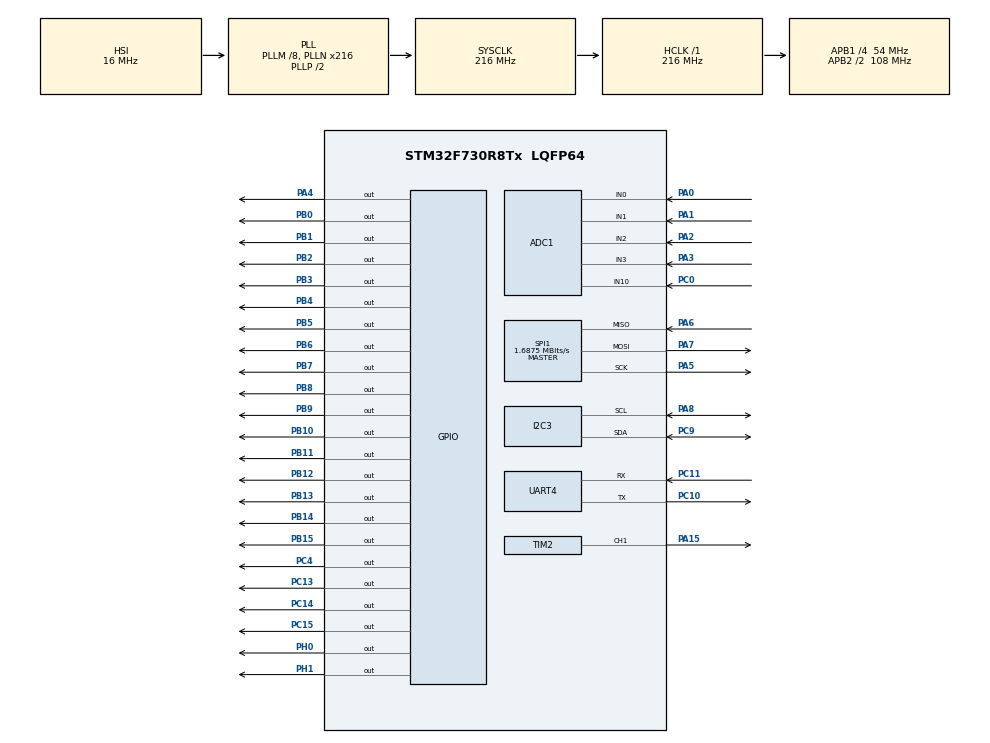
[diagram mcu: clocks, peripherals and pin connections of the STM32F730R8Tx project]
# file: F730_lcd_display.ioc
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ADC1.Channel-0\#ChannelRegularConversion=ADC_CHANNEL_0
ADC1.NbrOfConversionFlag=1
ADC1.Rank-0\#ChannelRegularConversion=1
ADC1.SamplingTime-0\#ChannelRegularConversion=ADC_SAMPLETIME_3CYCLES
ADC1.master=1
FREERTOS.Tasks01=thermostatT,24,64,ThermostatTask,As weak,NULL,Dynamic,NULL,NULL
FREERTOS.configMINIMAL_STACK_SIZE=64
I2C3.Speed=10
I2C3.Timing=0xA010E9FF
Mcu.Family=STM32F7
Mcu.Name=STM32F730R8Tx
Mcu.Package=LQFP64
NVIC.PriorityGroup=NVIC_PRIORITYGROUP_4
NVIC.TIM7_IRQn=true\:0\:0\:false\:false\:true\:false\:false\:true
NVIC.TimeBase=TIM7_IRQn
NVIC.TimeBaseIP=TIM7
NVIC.UART4_IRQn=true\:6\:0\:true\:false\:true\:false\:true\:true
PA0-WKUP.Signal=ADCx_IN0
PA1.Signal=ADCx_IN1
PA13.Mode=Serial_Wire
PA13.Signal=SYS_JTMS-SWDIO
PA14.Mode=Serial_Wire
PA14.Signal=SYS_JTCK-SWCLK
PA15.Signal=S_TIM2_CH1_ETR
PA2.Signal=ADCx_IN2
PA3.Signal=ADCx_IN3
PA4.Signal=GPIO_Output
PA5.Mode=Full_Duplex_Master
PA5.Signal=SPI1_SCK
PA6.Mode=Full_Duplex_Master
PA6.Signal=SPI1_MISO
PA7.Mode=Full_Duplex_Master
PA7.Signal=SPI1_MOSI
PA8.Mode=I2C
PA8.Signal=I2C3_SCL
PB0.Signal=GPIO_Output
PB1.Signal=GPIO_Output
PB10.Signal=GPIO_Output
PB11.Signal=GPIO_Output
PB12.Signal=GPIO_Output
PB13.Signal=GPIO_Output
PB14.Signal=GPIO_Output
PB15.Signal=GPIO_Output
PB2.Signal=GPIO_Output
PB3.Signal=GPIO_Output
PB4.Signal=GPIO_Output
PB5.Signal=GPIO_Output
PB6.Signal=GPIO_Output
PB7.Signal=GPIO_Output
PB8.Signal=GPIO_Output
PB9.Signal=GPIO_Output
PC0.Signal=ADCx_IN10
PC10.Mode=Asynchronous
PC10.Signal=UART4_TX
PC11.Mode=Asynchronous
PC11.Signal=UART4_RX
PC13.Signal=GPIO_Output
PC14-OSC32_IN.Signal=GPIO_Output
PC15-OSC32_OUT.Signal=GPIO_Output
PC4.Signal=GPIO_Output
PC9.Mode=I2C
PC9.Signal=I2C3_SDA
PH0-OSC_IN.Signal=GPIO_Output
PH1-OSC_OUT.Signal=GPIO_Output
ProjectManager.HeapSize=0x200
ProjectManager.StackSize=0x400
ProjectManager.TargetToolchain=STM32CubeIDE
RCC.AHBFreq_Value=216000000
RCC.APB1CLKDivider=RCC_HCLK_DIV4
RCC.APB1Freq_Value=54000000
RCC.APB1TimFreq_Value=108000000
RCC.APB2CLKDivider=RCC_HCLK_DIV2
RCC.APB2Freq_Value=108000000
RCC.APB2TimFreq_Value=216000000
RCC.CortexFreq_Value=216000000
RCC.HCLKFreq_Value=216000000
RCC.HSE_VALUE=25000000
RCC.HSI_VALUE=16000000
RCC.LSE_VALUE=32768
RCC.PLL48CLockSelection=RCC_CLK48SOURCE_PLLSAIP
RCC.PLLM=8
RCC.PLLN=216
RCC.PLLQ=9
RCC.PLLSAIP=RCC_PLLSAIP_DIV8
RCC.SYSCLKFreq_VALUE=216000000
RCC.SYSCLKSource=RCC_SYSCLKSOURCE_PLLCLK
RCC.UART4CLockSelection=RCC_UART4CLKSOURCE_SYSCLK
RCC.USBFreq_Value=48000000
RCC.VCOOutputFreq_Value=432000000
RTC.Format=RTC_FORMAT_BCD
RTC.StoreOperation=RTC_STOREOPERATION_SET
SH.ADCx_IN0.0=ADC1_IN0,IN0
SH.ADCx_IN1.0=ADC1_IN1,IN1
SH.ADCx_IN10.0=ADC1_IN10,IN10
SH.ADCx_IN2.0=ADC1_IN2,IN2
SH.ADCx_IN3.0=ADC1_IN3,IN3
SH.S_TIM2_CH1_ETR.0=TIM2_CH1,PWM Generation1 CH1
SPI1.BaudRatePrescaler=SPI_BAUDRATEPRESCALER_64
SPI1.CalculateBaudRate=1.6875 MBits/s
SPI1.DataSize=SPI_DATASIZE_8BIT
SPI1.Direction=SPI_DIRECTION_2LINES
SPI1.Mode=SPI_MODE_MASTER
SPI1.NSSPMode=SPI_NSS_PULSE_DISABLE
SPI1.VirtualType=VM_MASTER
TIM2.Channel-PWM\ Generation1\ CH1=TIM_CHANNEL_1
UART4.OneBitSampling=UART_ONE_BIT_SAMPLE_DISABLE
UART4.OverSampling=UART_OVERSAMPLING_16
VP_FREERTOS_VS_CMSIS_V2.Mode=CMSIS_V2
VP_RTC_VS_RTC_Activate.Mode=RTC_Enabled
VP_RTC_VS_RTC_Calendar.Mode=RTC_Calendar
VP_SYS_VS_tim7.Mode=TIM7
board=custom

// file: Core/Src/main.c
/* USER CODE BEGIN Header */
/**
  ******************************************************************************
  * @file           : main.c
  * @brief          : Main program body
  ******************************************************************************
  * @attention
  *
  * <h2><center>&copy; Copyright (c) 2020 STMicroelectronics.
  * All rights reserved.</center></h2>
  *
  * This software component is licensed by ST under BSD 3-Clause license,
  * the "License"; You may not use this file except in compliance with the
  * License. You may obtain a copy of the License at:
  *                        opensource.org/licenses/BSD-3-Clause
  *
  ******************************************************************************
  */
/* USER CODE END Header */
#include "main.h"
#include "cmsis_os.h"

/* USER CODE BEGIN Includes */
#include "main.h"
#include "SHT30.h"
#include "settings.h"
#include "programFunctions.h"
#include "uart.h"
/* USER CODE END Includes */

ADC_HandleTypeDef hadc1;

I2C_HandleTypeDef hi2c3;

RTC_HandleTypeDef hrtc;

SPI_HandleTypeDef hspi1;

TIM_HandleTypeDef htim2;

UART_HandleTypeDef huart4;

/* Definitions for thermostatT */
osThreadId_t thermostatTHandle;
const osThreadAttr_t thermostatT_attributes = {
  .name = "thermostatT",
  .priority = (osPriority_t) osPriorityNormal,
  .stack_size = 64 * 4
};

void SystemClock_Config(void);
static void MX_GPIO_Init(void);
static void MX_ADC1_Init(void);
static void MX_I2C3_Init(void);
static void MX_SPI1_Init(void);
static void MX_TIM2_Init(void);
static void MX_UART4_Init(void);
static void MX_RTC_Init(void);
void ThermostatTask(void *argument);

int main(void)
{

  /* MCU Configuration--------------------------------------------------------*/

  /* Reset of all peripherals, Initializes the Flash interface and the Systick. */
  HAL_Init();

  /* Configure the system clock */
  SystemClock_Config();

  /* Initialize all configured peripherals */
  MX_GPIO_Init();
  MX_ADC1_Init();
  MX_I2C3_Init();
  MX_SPI1_Init();
  MX_TIM2_Init();
  MX_UART4_Init();
  MX_RTC_Init();
  /* USER CODE BEGIN 2 */
  loadSettings();
  loadSchedule();
  resetComms();
  initAirSensor();

  /* USER CODE END 2 */

  /* Init scheduler */
  osKernelInitialize();

  /* Create the thread(s) */
  /* creation of thermostatT */
  thermostatTHandle = osThreadNew(ThermostatTask, NULL, &thermostatT_attributes);

  /* Start scheduler */
  osKernelStart();

  /* We should never get here as control is now taken by the scheduler */
  /* Infinite loop */
  while (1)
  {

  }
}

void SystemClock_Config(void)
{
  RCC_OscInitTypeDef RCC_OscInitStruct = {0};
  RCC_ClkInitTypeDef RCC_ClkInitStruct = {0};
  RCC_PeriphCLKInitTypeDef PeriphClkInitStruct = {0};

  /** Configure the main internal regulator output voltage
  */
  __HAL_RCC_PWR_CLK_ENABLE();
  __HAL_PWR_VOLTAGESCALING_CONFIG(PWR_REGULATOR_VOLTAGE_SCALE1);
  /** Initializes the RCC Oscillators according to the specified parameters
  * in the RCC_OscInitTypeDef structure.
  */
  RCC_OscInitStruct.OscillatorType = RCC_OSCILLATORTYPE_HSI|RCC_OSCILLATORTYPE_LSI;
  RCC_OscInitStruct.HSIState = RCC_HSI_ON;
  RCC_OscInitStruct.HSICalibrationValue = RCC_HSICALIBRATION_DEFAULT;
  RCC_OscInitStruct.LSIState = RCC_LSI_ON;
  RCC_OscInitStruct.PLL.PLLState = RCC_PLL_ON;
  RCC_OscInitStruct.PLL.PLLSource = RCC_PLLSOURCE_HSI;
  RCC_OscInitStruct.PLL.PLLM = 8;
  RCC_OscInitStruct.PLL.PLLN = 216;
  RCC_OscInitStruct.PLL.PLLP = RCC_PLLP_DIV2;
  RCC_OscInitStruct.PLL.PLLQ = 9;
  if (HAL_RCC_OscConfig(&RCC_OscInitStruct) != HAL_OK)
  {
    Error_Handler();
  }
  /** Activate the Over-Drive mode
  */
  if (HAL_PWREx_EnableOverDrive() != HAL_OK)
  {
    Error_Handler();
  }
  /** Initializes the CPU, AHB and APB buses clocks
  */
  RCC_ClkInitStruct.ClockType = RCC_CLOCKTYPE_HCLK|RCC_CLOCKTYPE_SYSCLK
                              |RCC_CLOCKTYPE_PCLK1|RCC_CLOCKTYPE_PCLK2;
  RCC_ClkInitStruct.SYSCLKSource = RCC_SYSCLKSOURCE_PLLCLK;
  RCC_ClkInitStruct.AHBCLKDivider = RCC_SYSCLK_DIV1;
  RCC_ClkInitStruct.APB1CLKDivider = RCC_HCLK_DIV4;
  RCC_ClkInitStruct.APB2CLKDivider = RCC_HCLK_DIV2;

  if (HAL_RCC_ClockConfig(&RCC_ClkInitStruct, FLASH_LATENCY_7) != HAL_OK)
  {
    Error_Handler();
  }
  PeriphClkInitStruct.PeriphClockSelection = RCC_PERIPHCLK_RTC|RCC_PERIPHCLK_UART4
                              |RCC_PERIPHCLK_I2C3;
  PeriphClkInitStruct.RTCClockSelection = RCC_RTCCLKSOURCE_LSI;
  PeriphClkInitStruct.Uart4ClockSelection = RCC_UART4CLKSOURCE_SYSCLK;
  PeriphClkInitStruct.I2c3ClockSelection = RCC_I2C3CLKSOURCE_PCLK1;
  if (HAL_RCCEx_PeriphCLKConfig(&PeriphClkInitStruct) != HAL_OK)
  {
    Error_Handler();
  }
}

static void MX_ADC1_Init(void)
{

  ADC_ChannelConfTypeDef sConfig = {0};

  /** Configure the global features of the ADC (Clock, Resolution, Data Alignment and number of conversion)
  */
  hadc1.Instance = ADC1;
  hadc1.Init.ClockPrescaler = ADC_CLOCK_SYNC_PCLK_DIV4;
  hadc1.Init.Resolution = ADC_RESOLUTION_12B;
  hadc1.Init.ScanConvMode = ADC_SCAN_DISABLE;
  hadc1.Init.ContinuousConvMode = DISABLE;
  hadc1.Init.DiscontinuousConvMode = DISABLE;
  hadc1.Init.ExternalTrigConvEdge = ADC_EXTERNALTRIGCONVEDGE_NONE;
  hadc1.Init.ExternalTrigConv = ADC_SOFTWARE_START;
  hadc1.Init.DataAlign = ADC_DATAALIGN_RIGHT;
  hadc1.Init.NbrOfConversion = 1;
  hadc1.Init.DMAContinuousRequests = DISABLE;
  hadc1.Init.EOCSelection = ADC_EOC_SINGLE_CONV;
  if (HAL_ADC_Init(&hadc1) != HAL_OK)
  {
    Error_Handler();
  }
  /** Configure for the selected ADC regular channel its corresponding rank in the sequencer and its sample time.
  */
  sConfig.Channel = ADC_CHANNEL_0;
  sConfig.Rank = ADC_REGULAR_RANK_1;
  sConfig.SamplingTime = ADC_SAMPLETIME_3CYCLES;
  if (HAL_ADC_ConfigChannel(&hadc1, &sConfig) != HAL_OK)
  {
    Error_Handler();
  }

}

static void MX_I2C3_Init(void)
{

  hi2c3.Instance = I2C3;
  hi2c3.Init.Timing = 0xA010E9FF;
  hi2c3.Init.OwnAddress1 = 0;
  hi2c3.Init.AddressingMode = I2C_ADDRESSINGMODE_7BIT;
  hi2c3.Init.DualAddressMode = I2C_DUALADDRESS_DISABLE;
  hi2c3.Init.OwnAddress2 = 0;
  hi2c3.Init.OwnAddress2Masks = I2C_OA2_NOMASK;
  hi2c3.Init.GeneralCallMode = I2C_GENERALCALL_DISABLE;
  hi2c3.Init.NoStretchMode = I2C_NOSTRETCH_DISABLE;
  if (HAL_I2C_Init(&hi2c3) != HAL_OK)
  {
    Error_Handler();
  }
  /** Configure Analogue filter
  */
  if (HAL_I2CEx_ConfigAnalogFilter(&hi2c3, I2C_ANALOGFILTER_ENABLE) != HAL_OK)
  {
    Error_Handler();
  }
  /** Configure Digital filter
  */
  if (HAL_I2CEx_ConfigDigitalFilter(&hi2c3, 0) != HAL_OK)
  {
    Error_Handler();
  }

}

static void MX_RTC_Init(void)
{

  RTC_TimeTypeDef sTime = {0};
  RTC_DateTypeDef sDate = {0};

  /** Initialize RTC Only
  */
  hrtc.Instance = RTC;
  hrtc.Init.HourFormat = RTC_HOURFORMAT_24;
  hrtc.Init.AsynchPrediv = 127;
  hrtc.Init.SynchPrediv = 255;
  hrtc.Init.OutPut = RTC_OUTPUT_DISABLE;
  hrtc.Init.OutPutPolarity = RTC_OUTPUT_POLARITY_HIGH;
  hrtc.Init.OutPutType = RTC_OUTPUT_TYPE_OPENDRAIN;
  if (HAL_RTC_Init(&hrtc) != HAL_OK)
  {
    Error_Handler();
  }

  /** Initialize RTC and set the Time and Date
  */
  sTime.Hours = 0x0;
  sTime.Minutes = 0x0;
  sTime.Seconds = 0x0;
  sTime.DayLightSaving = RTC_DAYLIGHTSAVING_NONE;
  sTime.StoreOperation = RTC_STOREOPERATION_SET;
  if (HAL_RTC_SetTime(&hrtc, &sTime, RTC_FORMAT_BCD) != HAL_OK)
  {
    Error_Handler();
  }
  sDate.WeekDay = RTC_WEEKDAY_MONDAY;
  sDate.Month = RTC_MONTH_JANUARY;
  sDate.Date = 0x1;
  sDate.Year = 0x0;

  if (HAL_RTC_SetDate(&hrtc, &sDate, RTC_FORMAT_BCD) != HAL_OK)
  {
    Error_Handler();
  }

}

static void MX_SPI1_Init(void)
{

  /* SPI1 parameter configuration*/
  hspi1.Instance = SPI1;
  hspi1.Init.Mode = SPI_MODE_MASTER;
  hspi1.Init.Direction = SPI_DIRECTION_2LINES;
  hspi1.Init.DataSize = SPI_DATASIZE_8BIT;
  hspi1.Init.CLKPolarity = SPI_POLARITY_LOW;
  hspi1.Init.CLKPhase = SPI_PHASE_1EDGE;
  hspi1.Init.NSS = SPI_NSS_SOFT;
  hspi1.Init.BaudRatePrescaler = SPI_BAUDRATEPRESCALER_64;
  hspi1.Init.FirstBit = SPI_FIRSTBIT_MSB;
  hspi1.Init.TIMode = SPI_TIMODE_DISABLE;
  hspi1.Init.CRCCalculation = SPI_CRCCALCULATION_DISABLE;
  hspi1.Init.CRCPolynomial = 7;
  hspi1.Init.CRCLength = SPI_CRC_LENGTH_DATASIZE;
  hspi1.Init.NSSPMode = SPI_NSS_PULSE_DISABLE;
  if (HAL_SPI_Init(&hspi1) != HAL_OK)
  {
    Error_Handler();
  }

}

static void MX_TIM2_Init(void)
{

  TIM_MasterConfigTypeDef sMasterConfig = {0};
  TIM_OC_InitTypeDef sConfigOC = {0};

  htim2.Instance = TIM2;
  htim2.Init.Prescaler = 0;
  htim2.Init.CounterMode = TIM_COUNTERMODE_UP;
  htim2.Init.Period = 4294967295;
  htim2.Init.ClockDivision = TIM_CLOCKDIVISION_DIV1;
  htim2.Init.AutoReloadPreload = TIM_AUTORELOAD_PRELOAD_DISABLE;
  if (HAL_TIM_PWM_Init(&htim2) != HAL_OK)
  {
    Error_Handler();
  }
  sMasterConfig.MasterOutputTrigger = TIM_TRGO_RESET;
  sMasterConfig.MasterSlaveMode = TIM_MASTERSLAVEMODE_DISABLE;
  if (HAL_TIMEx_MasterConfigSynchronization(&htim2, &sMasterConfig) != HAL_OK)
  {
    Error_Handler();
  }
  sConfigOC.OCMode = TIM_OCMODE_PWM1;
  sConfigOC.Pulse = 0;
  sConfigOC.OCPolarity = TIM_OCPOLARITY_HIGH;
  sConfigOC.OCFastMode = TIM_OCFAST_DISABLE;
  if (HAL_TIM_PWM_ConfigChannel(&htim2, &sConfigOC, TIM_CHANNEL_1) != HAL_OK)
  {
    Error_Handler();
  }
  HAL_TIM_MspPostInit(&htim2);

}

static void MX_UART4_Init(void)
{

  huart4.Instance = UART4;
  huart4.Init.BaudRate = 115200;
  huart4.Init.WordLength = UART_WORDLENGTH_8B;
  huart4.Init.StopBits = UART_STOPBITS_1;
  huart4.Init.Parity = UART_PARITY_NONE;
  huart4.Init.Mode = UART_MODE_TX_RX;
  huart4.Init.HwFlowCtl = UART_HWCONTROL_NONE;
  huart4.Init.OverSampling = UART_OVERSAMPLING_16;
  huart4.Init.OneBitSampling = UART_ONE_BIT_SAMPLE_DISABLE;
  huart4.AdvancedInit.AdvFeatureInit = UART_ADVFEATURE_NO_INIT;
  if (HAL_UART_Init(&huart4) != HAL_OK)
  {
    Error_Handler();
  }

}

static void MX_GPIO_Init(void)
{
  GPIO_InitTypeDef GPIO_InitStruct = {0};

  /* GPIO Ports Clock Enable */
  __HAL_RCC_GPIOC_CLK_ENABLE();
  __HAL_RCC_GPIOH_CLK_ENABLE();
  __HAL_RCC_GPIOA_CLK_ENABLE();
  __HAL_RCC_GPIOB_CLK_ENABLE();

  /*Configure GPIO pin Output Level */
  HAL_GPIO_WritePin(GPIOC, GPIO_PIN_13|GPIO_PIN_14|GPIO_PIN_15|GPIO_PIN_4, GPIO_PIN_RESET);

  /*Configure GPIO pin Output Level */
  HAL_GPIO_WritePin(GPIOH, GPIO_PIN_0|GPIO_PIN_1, GPIO_PIN_RESET);

  /*Configure GPIO pin Output Level */
  HAL_GPIO_WritePin(GPIOA, GPIO_PIN_4, GPIO_PIN_RESET);

  /*Configure GPIO pin Output Level */
  HAL_GPIO_WritePin(GPIOB, GPIO_PIN_0|GPIO_PIN_1|GPIO_PIN_2|GPIO_PIN_10
                          |GPIO_PIN_11|GPIO_PIN_12|GPIO_PIN_13|GPIO_PIN_14
                          |GPIO_PIN_15|GPIO_PIN_3|GPIO_PIN_4|GPIO_PIN_5
                          |GPIO_PIN_6|GPIO_PIN_7|GPIO_PIN_8|GPIO_PIN_9, GPIO_PIN_RESET);

  /*Configure GPIO pins : PC13 PC14 PC15 PC4 */
  GPIO_InitStruct.Pin = GPIO_PIN_13|GPIO_PIN_14|GPIO_PIN_15|GPIO_PIN_4;
  GPIO_InitStruct.Mode = GPIO_MODE_OUTPUT_PP;
  GPIO_InitStruct.Pull = GPIO_NOPULL;
  GPIO_InitStruct.Speed = GPIO_SPEED_FREQ_LOW;
  HAL_GPIO_Init(GPIOC, &GPIO_InitStruct);

  /*Configure GPIO pins : PH0 PH1 */
  GPIO_InitStruct.Pin = GPIO_PIN_0|GPIO_PIN_1;
  GPIO_InitStruct.Mode = GPIO_MODE_OUTPUT_PP;
  GPIO_InitStruct.Pull = GPIO_NOPULL;
  GPIO_InitStruct.Speed = GPIO_SPEED_FREQ_LOW;
  HAL_GPIO_Init(GPIOH, &GPIO_InitStruct);

  /*Configure GPIO pin : PA4 */
  GPIO_InitStruct.Pin = GPIO_PIN_4;
  GPIO_InitStruct.Mode = GPIO_MODE_OUTPUT_PP;
  GPIO_InitStruct.Pull = GPIO_NOPULL;
  GPIO_InitStruct.Speed = GPIO_SPEED_FREQ_LOW;
  HAL_GPIO_Init(GPIOA, &GPIO_InitStruct);

  /*Configure GPIO pins : PB0 PB1 PB2 PB10
                           PB11 PB12 PB13 PB14
                           PB15 PB3 PB4 PB5
                           PB6 PB7 PB8 PB9 */
  GPIO_InitStruct.Pin = GPIO_PIN_0|GPIO_PIN_1|GPIO_PIN_2|GPIO_PIN_10
                          |GPIO_PIN_11|GPIO_PIN_12|GPIO_PIN_13|GPIO_PIN_14
                          |GPIO_PIN_15|GPIO_PIN_3|GPIO_PIN_4|GPIO_PIN_5
                          |GPIO_PIN_6|GPIO_PIN_7|GPIO_PIN_8|GPIO_PIN_9;
  GPIO_InitStruct.Mode = GPIO_MODE_OUTPUT_PP;
  GPIO_InitStruct.Pull = GPIO_NOPULL;
  GPIO_InitStruct.Speed = GPIO_SPEED_FREQ_LOW;
  HAL_GPIO_Init(GPIOB, &GPIO_InitStruct);

}

__weak void ThermostatTask(void *argument)
{
  /* USER CODE BEGIN 5 */

	/*
	 * Task implemented in tasks.c
	 */

  /* Infinite loop */
  for(;;)
  {
	  osDelay(1000);
  }
  /* USER CODE END 5 */
}

 /**
  * @brief  Period elapsed callback in non blocking mode
  * @note   This function is called  when TIM7 interrupt took place, inside
  * HAL_TIM_IRQHandler(). It makes a direct call to HAL_IncTick() to increment
  * a global variable "uwTick" used as application time base.
  * @param  htim : TIM handle
  * @retval None
  */
void HAL_TIM_PeriodElapsedCallback(TIM_HandleTypeDef *htim)
{
  if (htim->Instance == TIM7) {
    HAL_IncTick();
  }
}

void Error_Handler(void)
{
}

/************************ (C) COPYRIGHT STMicroelectronics *****END OF FILE****/
